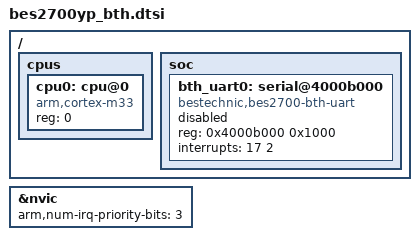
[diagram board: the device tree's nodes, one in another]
/*
 * SPDX-FileCopyrightText: Copyright The Zephyr Project Contributors
 * SPDX-License-Identifier: Apache-2.0
 */

#include <arm/armv8-m.dtsi>

/ {
	cpus {
		#address-cells = <1>;
		#size-cells = <0>;

		cpu0: cpu@0 {
			device_type = "cpu";
			compatible = "arm,cortex-m33";
			reg = <0>;
		};
	};

	soc {
		bth_uart0: serial@4000b000 {
			compatible = "bestechnic,bes2700-bth-uart";
			reg = <0x4000b000 0x1000>;
			interrupts = <17 2>;
			status = "disabled";
		};
	};
};

&nvic {
	arm,num-irq-priority-bits = <3>;
};
